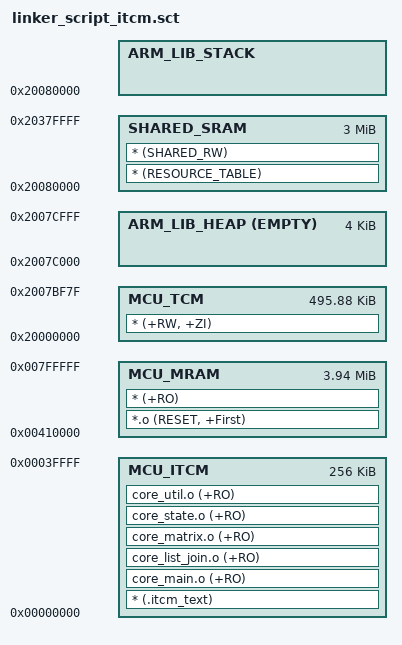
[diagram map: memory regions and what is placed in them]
;******************************************************************************
;
; linker_script_itcm.sct - Hybrid ITCM/MRAM scatter file for CoreMark power benchmark.
;
; CoreMark hot-path objects (~9.5 KB) execute from ITCM (zero-wait-state SRAM).
; HAL, NSX runtime, and libc stay in MRAM and execute via I-cache.
; ITCM content is stored in MRAM and copied at startup by the CRT.
;
;******************************************************************************

LR_1 0x00410000
{
    MCU_MRAM 0x00410000 0x003F0000
    {
        *.o (RESET, +First)
        * (+RO)
    }

    MCU_ITCM 0x00000000 0x00040000
    {
        * (.itcm_text)
        core_main.o (+RO)
        core_list_join.o (+RO)
        core_matrix.o (+RO)
        core_state.o (+RO)
        core_util.o (+RO)
    }

    MCU_TCM 0x20000000 (0x0007C000-0x80)
    {
        * (+RW, +ZI)
    }

    ARM_LIB_HEAP  0x2007C000 EMPTY  0x00001000
    {
    }

    SHARED_SRAM 0x20080000 0x00300000
    {
        * (RESOURCE_TABLE)
        * (SHARED_RW)
    }

    ARM_LIB_STACK 0x20080000 EMPTY - 0x00003000
    {
    }
}
